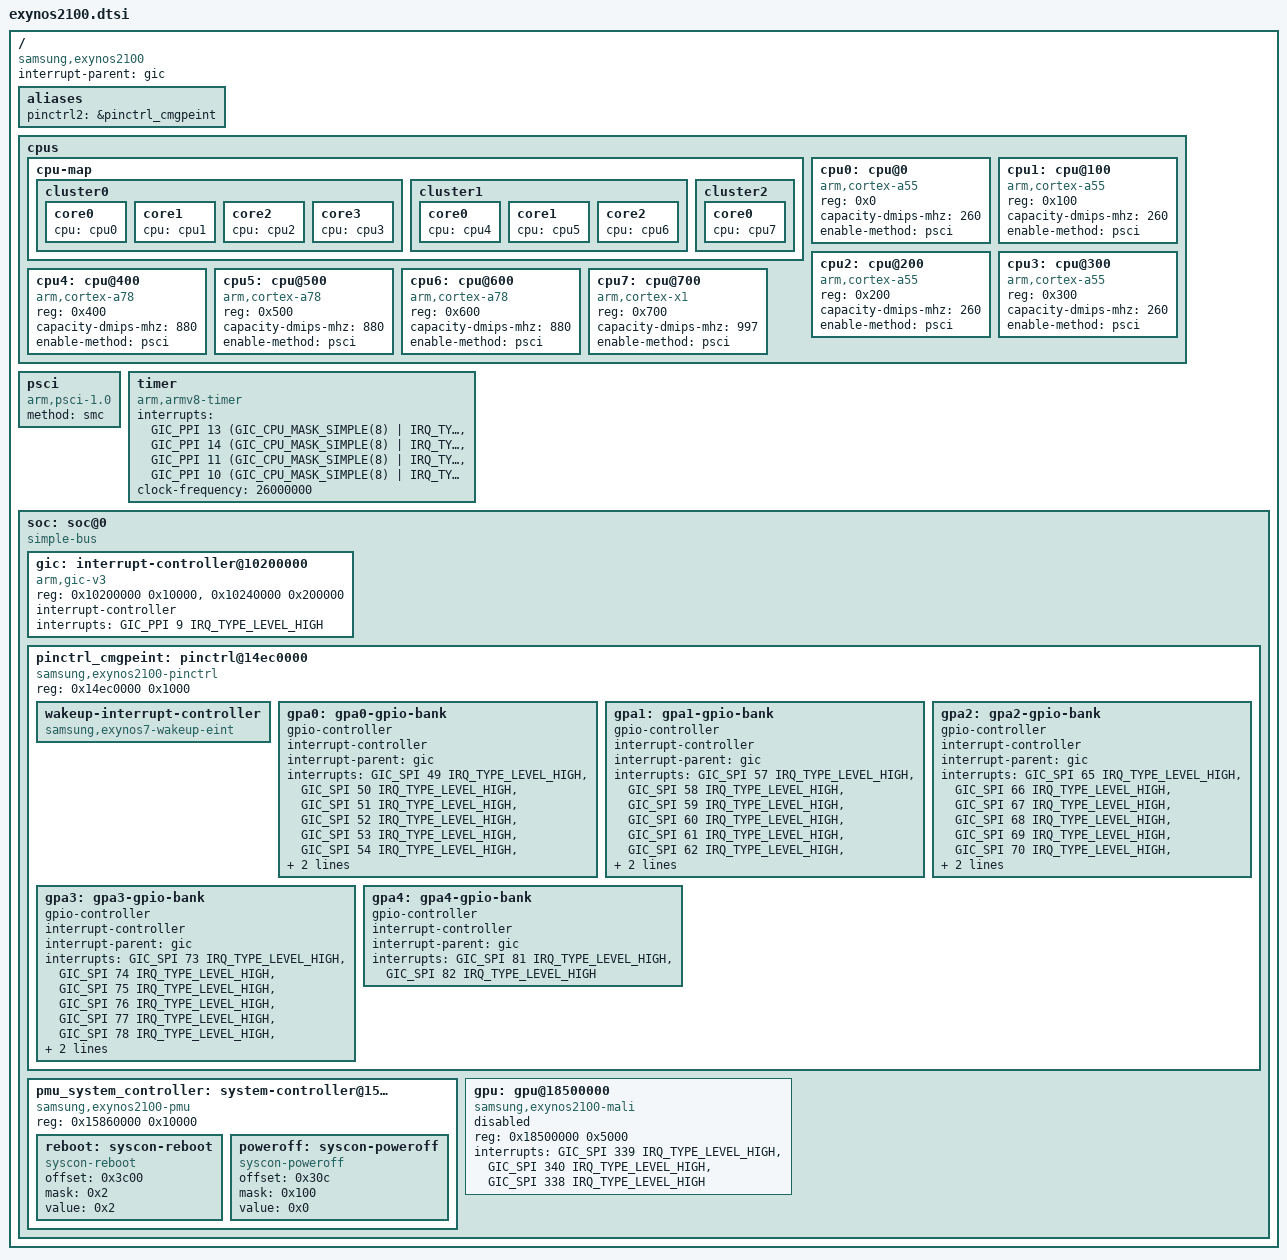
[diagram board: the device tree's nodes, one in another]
// SPDX-License-Identifier: GPL-2.0 OR BSD-3-Clause
/*
 * Samsung Exynos 2100 (S5E9840) SoC device tree source
 *
 * Minimal bring-up description. Register addresses and interrupt numbers
 * are taken from the vendor (Android 5.4) device tree; nothing here has
 * been validated against mainline bindings.
 */

#include <dt-bindings/interrupt-controller/arm-gic.h>

/ {
	compatible = "samsung,exynos2100";
	#address-cells = <2>;
	#size-cells = <2>;

	interrupt-parent = <&gic>;

	aliases {
		/* Index must match exynos2100_pin_ctrl[] in the pinctrl driver */
		pinctrl2 = &pinctrl_cmgpeint;
	};

	cpus {
		#address-cells = <1>;
		#size-cells = <0>;

		cpu-map {
			cluster0 {
				core0 {
					cpu = <&cpu0>;
				};

				core1 {
					cpu = <&cpu1>;
				};

				core2 {
					cpu = <&cpu2>;
				};

				core3 {
					cpu = <&cpu3>;
				};
			};

			cluster1 {
				core0 {
					cpu = <&cpu4>;
				};

				core1 {
					cpu = <&cpu5>;
				};

				core2 {
					cpu = <&cpu6>;
				};
			};

			cluster2 {
				core0 {
					cpu = <&cpu7>;
				};
			};
		};

		cpu0: cpu@0 {
			device_type = "cpu";
			compatible = "arm,cortex-a55";
			reg = <0x0>;
			capacity-dmips-mhz = <260>;
			enable-method = "psci";
		};

		cpu1: cpu@100 {
			device_type = "cpu";
			compatible = "arm,cortex-a55";
			reg = <0x100>;
			capacity-dmips-mhz = <260>;
			enable-method = "psci";
		};

		cpu2: cpu@200 {
			device_type = "cpu";
			compatible = "arm,cortex-a55";
			reg = <0x200>;
			capacity-dmips-mhz = <260>;
			enable-method = "psci";
		};

		cpu3: cpu@300 {
			device_type = "cpu";
			compatible = "arm,cortex-a55";
			reg = <0x300>;
			capacity-dmips-mhz = <260>;
			enable-method = "psci";
		};

		cpu4: cpu@400 {
			device_type = "cpu";
			compatible = "arm,cortex-a78";
			reg = <0x400>;
			capacity-dmips-mhz = <880>;
			enable-method = "psci";
		};

		cpu5: cpu@500 {
			device_type = "cpu";
			compatible = "arm,cortex-a78";
			reg = <0x500>;
			capacity-dmips-mhz = <880>;
			enable-method = "psci";
		};

		cpu6: cpu@600 {
			device_type = "cpu";
			compatible = "arm,cortex-a78";
			reg = <0x600>;
			capacity-dmips-mhz = <880>;
			enable-method = "psci";
		};

		cpu7: cpu@700 {
			device_type = "cpu";
			compatible = "arm,cortex-x1";
			reg = <0x700>;
			capacity-dmips-mhz = <997>;
			enable-method = "psci";
		};
	};

	psci {
		compatible = "arm,psci-1.0";
		method = "smc";
	};

	timer {
		compatible = "arm,armv8-timer";
		interrupts = <GIC_PPI 13 (GIC_CPU_MASK_SIMPLE(8) | IRQ_TYPE_LEVEL_LOW)>,
			     <GIC_PPI 14 (GIC_CPU_MASK_SIMPLE(8) | IRQ_TYPE_LEVEL_LOW)>,
			     <GIC_PPI 11 (GIC_CPU_MASK_SIMPLE(8) | IRQ_TYPE_LEVEL_LOW)>,
			     <GIC_PPI 10 (GIC_CPU_MASK_SIMPLE(8) | IRQ_TYPE_LEVEL_LOW)>;
		/*
		 * The bootloader does not program CNTFRQ_EL0 on every core;
		 * the vendor tree carries the same override.
		 */
		clock-frequency = <26000000>;
	};

	soc: soc@0 {
		compatible = "simple-bus";
		ranges = <0x0 0x0 0x0 0x20000000>;
		#address-cells = <1>;
		#size-cells = <1>;

		gic: interrupt-controller@10200000 {
			compatible = "arm,gic-v3";
			reg = <0x10200000 0x10000>,	/* GICD */
			      <0x10240000 0x200000>;	/* GICR * 8 */
			#interrupt-cells = <3>;
			interrupt-controller;
			interrupts = <GIC_PPI 9 IRQ_TYPE_LEVEL_HIGH>;
		};

		pinctrl_cmgpeint: pinctrl@14ec0000 {
			compatible = "samsung,exynos2100-pinctrl";
			reg = <0x14ec0000 0x1000>;

			wakeup-interrupt-controller {
				compatible = "samsung,exynos7-wakeup-eint";
			};

			gpa0: gpa0-gpio-bank {
				gpio-controller;
				#gpio-cells = <2>;
				interrupt-controller;
				#interrupt-cells = <2>;
				interrupt-parent = <&gic>;
				interrupts = <GIC_SPI 49 IRQ_TYPE_LEVEL_HIGH>,
					     <GIC_SPI 50 IRQ_TYPE_LEVEL_HIGH>,
					     <GIC_SPI 51 IRQ_TYPE_LEVEL_HIGH>,
					     <GIC_SPI 52 IRQ_TYPE_LEVEL_HIGH>,
					     <GIC_SPI 53 IRQ_TYPE_LEVEL_HIGH>,
					     <GIC_SPI 54 IRQ_TYPE_LEVEL_HIGH>,
					     <GIC_SPI 55 IRQ_TYPE_LEVEL_HIGH>,
					     <GIC_SPI 56 IRQ_TYPE_LEVEL_HIGH>;
			};

			gpa1: gpa1-gpio-bank {
				gpio-controller;
				#gpio-cells = <2>;
				interrupt-controller;
				#interrupt-cells = <2>;
				interrupt-parent = <&gic>;
				interrupts = <GIC_SPI 57 IRQ_TYPE_LEVEL_HIGH>,
					     <GIC_SPI 58 IRQ_TYPE_LEVEL_HIGH>,
					     <GIC_SPI 59 IRQ_TYPE_LEVEL_HIGH>,
					     <GIC_SPI 60 IRQ_TYPE_LEVEL_HIGH>,
					     <GIC_SPI 61 IRQ_TYPE_LEVEL_HIGH>,
					     <GIC_SPI 62 IRQ_TYPE_LEVEL_HIGH>,
					     <GIC_SPI 63 IRQ_TYPE_LEVEL_HIGH>,
					     <GIC_SPI 64 IRQ_TYPE_LEVEL_HIGH>;
			};

			gpa2: gpa2-gpio-bank {
				gpio-controller;
				#gpio-cells = <2>;
				interrupt-controller;
				#interrupt-cells = <2>;
				interrupt-parent = <&gic>;
				interrupts = <GIC_SPI 65 IRQ_TYPE_LEVEL_HIGH>,
					     <GIC_SPI 66 IRQ_TYPE_LEVEL_HIGH>,
					     <GIC_SPI 67 IRQ_TYPE_LEVEL_HIGH>,
					     <GIC_SPI 68 IRQ_TYPE_LEVEL_HIGH>,
					     <GIC_SPI 69 IRQ_TYPE_LEVEL_HIGH>,
					     <GIC_SPI 70 IRQ_TYPE_LEVEL_HIGH>,
					     <GIC_SPI 71 IRQ_TYPE_LEVEL_HIGH>,
					     <GIC_SPI 72 IRQ_TYPE_LEVEL_HIGH>;
			};

			gpa3: gpa3-gpio-bank {
				gpio-controller;
				#gpio-cells = <2>;
				interrupt-controller;
				#interrupt-cells = <2>;
				interrupt-parent = <&gic>;
				interrupts = <GIC_SPI 73 IRQ_TYPE_LEVEL_HIGH>,
					     <GIC_SPI 74 IRQ_TYPE_LEVEL_HIGH>,
					     <GIC_SPI 75 IRQ_TYPE_LEVEL_HIGH>,
					     <GIC_SPI 76 IRQ_TYPE_LEVEL_HIGH>,
					     <GIC_SPI 77 IRQ_TYPE_LEVEL_HIGH>,
					     <GIC_SPI 78 IRQ_TYPE_LEVEL_HIGH>,
					     <GIC_SPI 79 IRQ_TYPE_LEVEL_HIGH>,
					     <GIC_SPI 80 IRQ_TYPE_LEVEL_HIGH>;
			};

			gpa4: gpa4-gpio-bank {
				gpio-controller;
				#gpio-cells = <2>;
				interrupt-controller;
				#interrupt-cells = <2>;
				interrupt-parent = <&gic>;
				interrupts = <GIC_SPI 81 IRQ_TYPE_LEVEL_HIGH>,
					     <GIC_SPI 82 IRQ_TYPE_LEVEL_HIGH>;
			};
		};

		pmu_system_controller: system-controller@15860000 {
			compatible = "samsung,exynos2100-pmu", "syscon", "simple-mfd";
			reg = <0x15860000 0x10000>;

			/* Offsets from the vendor "samsung,exynos-reboot" node */
			reboot: syscon-reboot {
				compatible = "syscon-reboot";
				offset = <0x3c00>;	/* SYSTEM_CONFIGURATION */
				mask = <0x2>;
				value = <0x2>;
			};

			poweroff: syscon-poweroff {
				compatible = "syscon-poweroff";
				offset = <0x30c>;	/* PS_HOLD_CONTROL */
				mask = <0x100>;
				value = <0x0>;
			};
		};

		/*
		 * Mali-G78 MP14 (Valhall, job-manager). Kept disabled: it needs
		 * the G3D power domain, CMU_G3D clock and the PMIC rail (via
		 * ACPM), none of which have mainline drivers yet.
		 */
		gpu: gpu@18500000 {
			compatible = "samsung,exynos2100-mali", "arm,mali-valhall-jm";
			reg = <0x18500000 0x5000>;
			interrupts = <GIC_SPI 339 IRQ_TYPE_LEVEL_HIGH>,
				     <GIC_SPI 340 IRQ_TYPE_LEVEL_HIGH>,
				     <GIC_SPI 338 IRQ_TYPE_LEVEL_HIGH>;
			interrupt-names = "job", "mmu", "gpu";
			status = "disabled";
		};
	};
};
